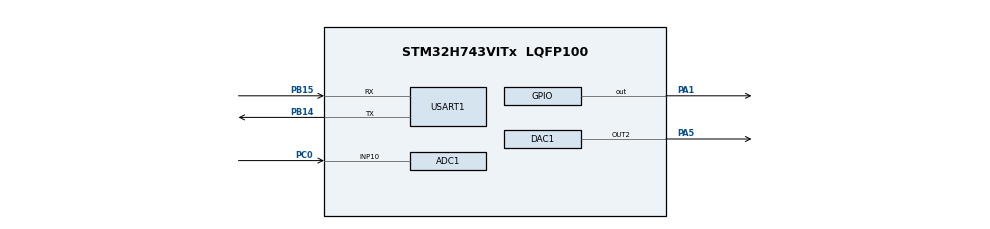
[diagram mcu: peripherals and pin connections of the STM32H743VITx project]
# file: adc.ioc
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ADC1.Channel-0\#ChannelRegularConversion=ADC_CHANNEL_10
ADC1.ConversionDataManagement=ADC_CONVERSIONDATA_DMA_CIRCULAR
ADC1.ExternalTrigConv=ADC_EXTERNALTRIG_T15_TRGO
ADC1.NbrOfConversion=1
ADC1.NbrOfConversionFlag=1
ADC1.OffsetNumber-0\#ChannelRegularConversion=ADC_OFFSET_NONE
ADC1.OffsetSignedSaturation-0\#ChannelRegularConversion=DISABLE
ADC1.Rank-0\#ChannelRegularConversion=1
ADC1.SamplingTime-0\#ChannelRegularConversion=ADC_SAMPLETIME_1CYCLE_5
ADC1.master=1
CORTEX_M7.AccessPermission-Cortex_Memory_Protection_Unit_Region0_Settings=MPU_REGION_FULL_ACCESS
CORTEX_M7.AccessPermission-Cortex_Memory_Protection_Unit_Region1_Settings=MPU_REGION_FULL_ACCESS
CORTEX_M7.AccessPermission-Cortex_Memory_Protection_Unit_Region2_Settings=MPU_REGION_FULL_ACCESS
CORTEX_M7.AccessPermission-Cortex_Memory_Protection_Unit_Region3_Settings=MPU_REGION_FULL_ACCESS
CORTEX_M7.AccessPermission-Cortex_Memory_Protection_Unit_Region4_Settings=MPU_REGION_FULL_ACCESS
CORTEX_M7.BaseAddress-Cortex_Memory_Protection_Unit_Region0_Settings=0x24000000
CORTEX_M7.BaseAddress-Cortex_Memory_Protection_Unit_Region1_Settings=0x30000000
CORTEX_M7.BaseAddress-Cortex_Memory_Protection_Unit_Region2_Settings=0x30020000
CORTEX_M7.BaseAddress-Cortex_Memory_Protection_Unit_Region3_Settings=0x30040000
CORTEX_M7.BaseAddress-Cortex_Memory_Protection_Unit_Region4_Settings=0x38000000
CORTEX_M7.CPU_DCache=Enabled
CORTEX_M7.CPU_ICache=Enabled
CORTEX_M7.Enable-Cortex_Memory_Protection_Unit_Region0_Settings=MPU_REGION_ENABLE
CORTEX_M7.Enable-Cortex_Memory_Protection_Unit_Region1_Settings=MPU_REGION_ENABLE
CORTEX_M7.Enable-Cortex_Memory_Protection_Unit_Region2_Settings=MPU_REGION_ENABLE
CORTEX_M7.Enable-Cortex_Memory_Protection_Unit_Region3_Settings=MPU_REGION_ENABLE
CORTEX_M7.Enable-Cortex_Memory_Protection_Unit_Region4_Settings=MPU_REGION_ENABLE
CORTEX_M7.Enable-Cortex_Memory_Protection_Unit_Region5_Settings=__NULL
CORTEX_M7.IsBufferable-Cortex_Memory_Protection_Unit_Region0_Settings=MPU_ACCESS_BUFFERABLE
CORTEX_M7.IsCacheable-Cortex_Memory_Protection_Unit_Region0_Settings=MPU_ACCESS_CACHEABLE
CORTEX_M7.MPU_Control=MPU_PRIVILEGED_DEFAULT
CORTEX_M7.Size-Cortex_Memory_Protection_Unit_Region0_Settings=MPU_REGION_SIZE_512KB
CORTEX_M7.Size-Cortex_Memory_Protection_Unit_Region1_Settings=MPU_REGION_SIZE_128KB
CORTEX_M7.Size-Cortex_Memory_Protection_Unit_Region2_Settings=MPU_REGION_SIZE_128KB
CORTEX_M7.Size-Cortex_Memory_Protection_Unit_Region3_Settings=MPU_REGION_SIZE_32KB
CORTEX_M7.Size-Cortex_Memory_Protection_Unit_Region4_Settings=MPU_REGION_SIZE_64KB
CORTEX_M7.TypeExtField-Cortex_Memory_Protection_Unit_Region0_Settings=MPU_TEX_LEVEL1
CORTEX_M7.TypeExtField-Cortex_Memory_Protection_Unit_Region1_Settings=MPU_TEX_LEVEL1
CORTEX_M7.TypeExtField-Cortex_Memory_Protection_Unit_Region2_Settings=MPU_TEX_LEVEL1
CORTEX_M7.TypeExtField-Cortex_Memory_Protection_Unit_Region3_Settings=MPU_TEX_LEVEL1
CORTEX_M7.TypeExtField-Cortex_Memory_Protection_Unit_Region4_Settings=MPU_TEX_LEVEL1
DAC1.DAC2_OutputBuffer-DAC_OUT2=DAC_OUTPUTBUFFER_DISABLE
DAC1.DAC_Channel-DAC_OUT2=DAC_CHANNEL_2
DAC1.DAC_Trigger-DAC_OUT2=DAC_TRIGGER_SOFTWARE
Dma.ADC1.0.Direction=DMA_PERIPH_TO_MEMORY
Dma.ADC1.0.EventEnable=DISABLE
Dma.ADC1.0.FIFOMode=DMA_FIFOMODE_DISABLE
Dma.ADC1.0.Instance=DMA1_Stream0
Dma.ADC1.0.MemDataAlignment=DMA_MDATAALIGN_HALFWORD
Dma.ADC1.0.MemInc=DMA_MINC_ENABLE
Dma.ADC1.0.Mode=DMA_NORMAL
Dma.ADC1.0.PeriphDataAlignment=DMA_PDATAALIGN_HALFWORD
Dma.ADC1.0.PeriphInc=DMA_PINC_DISABLE
Dma.ADC1.0.Polarity=HAL_DMAMUX_REQ_GEN_RISING
Dma.ADC1.0.Priority=DMA_PRIORITY_LOW
Dma.ADC1.0.RequestNumber=1
Dma.ADC1.0.SignalID=NONE
Dma.ADC1.0.SyncEnable=DISABLE
Dma.ADC1.0.SyncPolarity=HAL_DMAMUX_SYNC_NO_EVENT
Dma.ADC1.0.SyncRequestNumber=1
Dma.ADC1.0.SyncSignalID=NONE
Dma.DAC1_CH2.1.Direction=DMA_MEMORY_TO_PERIPH
Dma.DAC1_CH2.1.EventEnable=DISABLE
Dma.DAC1_CH2.1.FIFOMode=DMA_FIFOMODE_DISABLE
Dma.DAC1_CH2.1.Instance=DMA1_Stream1
Dma.DAC1_CH2.1.MemDataAlignment=DMA_MDATAALIGN_HALFWORD
Dma.DAC1_CH2.1.MemInc=DMA_MINC_ENABLE
Dma.DAC1_CH2.1.Mode=DMA_CIRCULAR
Dma.DAC1_CH2.1.PeriphDataAlignment=DMA_PDATAALIGN_HALFWORD
Dma.DAC1_CH2.1.PeriphInc=DMA_PINC_DISABLE
Dma.DAC1_CH2.1.Polarity=HAL_DMAMUX_REQ_GEN_RISING
Dma.DAC1_CH2.1.Priority=DMA_PRIORITY_LOW
Dma.DAC1_CH2.1.RequestNumber=1
Dma.DAC1_CH2.1.SignalID=NONE
Dma.DAC1_CH2.1.SyncEnable=DISABLE
Dma.DAC1_CH2.1.SyncPolarity=HAL_DMAMUX_SYNC_NO_EVENT
Dma.DAC1_CH2.1.SyncRequestNumber=1
Dma.DAC1_CH2.1.SyncSignalID=NONE
Dma.Request0=ADC1
Dma.Request1=DAC1_CH2
Mcu.Family=STM32H7
Mcu.Name=STM32H743VITx
Mcu.Package=LQFP100
NVIC.DMA1_Stream0_IRQn=true\:0\:0\:false\:false\:true\:false\:true\:true
NVIC.DMA1_Stream1_IRQn=true\:0\:0\:false\:false\:true\:false\:true\:true
NVIC.PriorityGroup=NVIC_PRIORITYGROUP_4
NVIC.USART1_IRQn=true\:0\:0\:false\:false\:true\:true\:true\:true
PA1.GPIO_PuPd=GPIO_PULLDOWN
PA1.Signal=GPIO_Output
PA13\ (JTMS/SWDIO).Mode=Serial_Wire
PA13\ (JTMS/SWDIO).Signal=DEBUG_JTMS-SWDIO
PA14\ (JTCK/SWCLK).Mode=Serial_Wire
PA14\ (JTCK/SWCLK).Signal=DEBUG_JTCK-SWCLK
PA5.Signal=COMP_DAC12_group
PB14.Mode=Asynchronous
PB14.Signal=USART1_TX
PB15.Mode=Asynchronous
PB15.Signal=USART1_RX
PC0.Signal=ADCx_INP10
PH0-OSC_IN\ (PH0).Mode=HSE-External-Oscillator
PH0-OSC_IN\ (PH0).Signal=RCC_OSC_IN
PH1-OSC_OUT\ (PH1).Mode=HSE-External-Oscillator
PH1-OSC_OUT\ (PH1).Signal=RCC_OSC_OUT
ProjectManager.HeapSize=0x200
ProjectManager.StackSize=0x7400
ProjectManager.TargetToolchain=MDK-ARM V5.32
RCC.ADCFreq_Value=72000000
RCC.APB1Freq_Value=120000000
RCC.APB2Freq_Value=120000000
RCC.APB3Freq_Value=120000000
RCC.APB4Freq_Value=120000000
RCC.CSICalibrationValue=32
RCC.CortexFreq_Value=480000000
RCC.D1PPRE=RCC_APB3_DIV2
RCC.D2PPRE1=RCC_APB1_DIV2
RCC.D2PPRE2=RCC_APB2_DIV2
RCC.D3PPRE=RCC_APB4_DIV2
RCC.DIVM1=5
RCC.DIVM2=25
RCC.DIVN1=192
RCC.DIVN2=360
RCC.DIVP2=5
RCC.FLatency=FLASH_LATENCY_4
RCC.HCLKFreq_Value=240000000
RCC.HPRE=RCC_HCLK_DIV2
RCC.HSE_Timout=5000
RCC.PLLSourceVirtual=RCC_PLLSOURCE_HSE
RCC.ProductRev=revV
RCC.SYSCLKFreq_VALUE=480000000
RCC.SYSCLKSource=RCC_SYSCLKSOURCE_PLLCLK
RCC.USBFreq_Value=480000000
SH.ADCx_INP10.0=ADC1_INP10,IN10-Single-Ended
SH.COMP_DAC12_group.0=DAC1_OUT2,DAC_OUT2
STMicroelectronics.X-CUBE-ALGOBUILD.1.3.0.LibraryCcDSPOoLibraryJjDSPOoLibrary=true
TIM15.AutoReloadPreload=TIM_AUTORELOAD_PRELOAD_ENABLE
TIM15.Period=2399
TIM15.Prescaler=0
TIM15.TIM_MasterOutputTrigger=TIM_TRGO_UPDATE
TIM7.Prescaler=239
USART1.VirtualMode-Asynchronous=VM_ASYNC
VP_STMicroelectronics.X-CUBE-ALGOBUILD_VS_DSPOoLibraryJjLibrary_1.3.0_1.3.0.Mode=DSPOoLibraryJjLibrary
VP_TIM15_VS_ClockSourceINT.Mode=Internal
VP_TIM7_VS_ClockSourceINT.Mode=Enable_Timer
board=custom

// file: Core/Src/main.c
/* USER CODE BEGIN Header */
/**
  ******************************************************************************
  * @file           : main.c
  * @brief          : Main program body
  ******************************************************************************
  * @attention
  *
  * Copyright (c) 2023 STMicroelectronics.
  * All rights reserved.
  *
  * This software is licensed under terms that can be found in the LICENSE file
  * in the root directory of this software component.
  * If no LICENSE file comes with this software, it is provided AS-IS.
  *
  ******************************************************************************
  */
/* USER CODE END Header */
#include "main.h"
#include "adc.h"
#include "dac.h"
#include "dma.h"
#include "tim.h"
#include "usart.h"
#include "gpio.h"

/* USER CODE BEGIN PTD */

//ALIGN_32BYTES (uint16_t adc1_data[FFT_LENGTH]) 	__attribute__((section(".ARM.__at_0x30000000")));
//__IO uint8_t AdcConvEnd = 0;//表示adc采集完成
//void adc_init(void)
//{
//	printf("start_adc\n");
//	MX_ADC1_Init();	//初始化调用放这里, 确保在MX_DMA_Init()初始化后面
//	HAL_Delay(100);	//有地方说这里可以等等电压稳定后再校准

//	if (HAL_ADCEx_Calibration_Start(&hadc1, ADC_CALIB_OFFSET, ADC_SINGLE_ENDED) != HAL_OK)
//	{
//			printf("hadc1 error with HAL_ADCEx_Calibration_Start\r\n");
//			Error_Handler();
//	}

//	if (HAL_ADC_Start_DMA(&hadc1, (uint32_t *)adc1_data, FFT_LENGTH) != HAL_OK)
//	{
//			printf("hadc1 error with HAL_ADC_Start_DMA\r\n");
//			Error_Handler();
//	}

//	HAL_TIM_Base_Start(&htim15);
//	while (!AdcConvEnd);
//	AdcConvEnd = 0;
//	HAL_ADC_DeInit(&hadc1);
//	HAL_TIM_Base_Stop(&htim15);
//}
/* USER CODE END PTD */

/* USER CODE BEGIN PV */
uint16_t adc_buff[200];//存放ADC采集的数据
/*
AdcConvEnd用来检测ADC是否采集完毕
0：没有采集完毕
1：采集完毕，在stm32f1xx_it里的DMA完成中断进行修改
 */
__IO uint8_t AdcConvEnd = 0;

/* USER CODE END PV */

void SystemClock_Config(void);
static void MPU_Initialize(void);
static void MPU_Config(void);

int main(void)
{

  /* Enable I-Cache---------------------------------------------------------*/
  SCB_EnableICache();

  /* Enable D-Cache---------------------------------------------------------*/
  SCB_EnableDCache();

  /* MCU Configuration--------------------------------------------------------*/

  /* Reset of all peripherals, Initializes the Flash interface and the Systick. */
  HAL_Init();

  /* MPU Configuration--------------------------------------------------------*/
  MPU_Config();

  /* Configure the system clock */
  SystemClock_Config();

  /* Initialize all configured peripherals */
  MX_GPIO_Init();
  MX_DMA_Init();
  MX_USART1_UART_Init();
  MX_ADC1_Init();
  MX_TIM7_Init();
  MX_DAC1_Init();
  MX_TIM15_Init();
  /* USER CODE BEGIN 2 */
  HAL_TIM_Base_Start(&htim15);                           //开启定时器3
//HAL_ADCEx_Calibration_Start(&hadc1);                  //AD校准
HAL_ADC_Start_DMA(&hadc1, (uint32_t *)adc_buff, 200); //让ADC1去采集200个数，存放到adc_buff数组里
while (!AdcConvEnd)                                   //等待转换完毕
    ;
for (uint16_t i = 0; i < 200; i++)
{
    printf("%.3f\n", adc_buff[i] * 3.3 / 4095); //数据打印，查看结果
}

//  HAL_DAC_SetValue(&hdac1,DAC_CHANNEL_2,DAC_ALIGN_12B_R,4095);
//  HAL_DAC_Start(&hdac1,DAC_CHANNEL_2);
//
//  adc_init();
//  for (u16 temp = 0; temp< FFT_LENGTH;temp++)
//	{
//		printf("%d\r\n", adc1_data[temp]);
//	}
  /* USER CODE END 2 */

  /* Infinite loop */
  while (1)
  {

  }
}

void SystemClock_Config(void)
{
  RCC_OscInitTypeDef RCC_OscInitStruct = {0};
  RCC_ClkInitTypeDef RCC_ClkInitStruct = {0};

  /** Supply configuration update enable
  */
  HAL_PWREx_ConfigSupply(PWR_LDO_SUPPLY);

  /** Configure the main internal regulator output voltage
  */
  __HAL_PWR_VOLTAGESCALING_CONFIG(PWR_REGULATOR_VOLTAGE_SCALE1);

  while(!__HAL_PWR_GET_FLAG(PWR_FLAG_VOSRDY)) {}

  __HAL_RCC_SYSCFG_CLK_ENABLE();
  __HAL_PWR_VOLTAGESCALING_CONFIG(PWR_REGULATOR_VOLTAGE_SCALE0);

  while(!__HAL_PWR_GET_FLAG(PWR_FLAG_VOSRDY)) {}

  /** Initializes the RCC Oscillators according to the specified parameters
  * in the RCC_OscInitTypeDef structure.
  */
  RCC_OscInitStruct.OscillatorType = RCC_OSCILLATORTYPE_HSE;
  RCC_OscInitStruct.HSEState = RCC_HSE_ON;
  RCC_OscInitStruct.PLL.PLLState = RCC_PLL_ON;
  RCC_OscInitStruct.PLL.PLLSource = RCC_PLLSOURCE_HSE;
  RCC_OscInitStruct.PLL.PLLM = 5;
  RCC_OscInitStruct.PLL.PLLN = 192;
  RCC_OscInitStruct.PLL.PLLP = 2;
  RCC_OscInitStruct.PLL.PLLQ = 2;
  RCC_OscInitStruct.PLL.PLLR = 2;
  RCC_OscInitStruct.PLL.PLLRGE = RCC_PLL1VCIRANGE_2;
  RCC_OscInitStruct.PLL.PLLVCOSEL = RCC_PLL1VCOWIDE;
  RCC_OscInitStruct.PLL.PLLFRACN = 0;
  if (HAL_RCC_OscConfig(&RCC_OscInitStruct) != HAL_OK)
  {
    Error_Handler();
  }

  /** Initializes the CPU, AHB and APB buses clocks
  */
  RCC_ClkInitStruct.ClockType = RCC_CLOCKTYPE_HCLK|RCC_CLOCKTYPE_SYSCLK
                              |RCC_CLOCKTYPE_PCLK1|RCC_CLOCKTYPE_PCLK2
                              |RCC_CLOCKTYPE_D3PCLK1|RCC_CLOCKTYPE_D1PCLK1;
  RCC_ClkInitStruct.SYSCLKSource = RCC_SYSCLKSOURCE_PLLCLK;
  RCC_ClkInitStruct.SYSCLKDivider = RCC_SYSCLK_DIV1;
  RCC_ClkInitStruct.AHBCLKDivider = RCC_HCLK_DIV2;
  RCC_ClkInitStruct.APB3CLKDivider = RCC_APB3_DIV2;
  RCC_ClkInitStruct.APB1CLKDivider = RCC_APB1_DIV2;
  RCC_ClkInitStruct.APB2CLKDivider = RCC_APB2_DIV2;
  RCC_ClkInitStruct.APB4CLKDivider = RCC_APB4_DIV2;

  if (HAL_RCC_ClockConfig(&RCC_ClkInitStruct, FLASH_LATENCY_4) != HAL_OK)
  {
    Error_Handler();
  }
}

/* USER CODE BEGIN 4 */
void HAL_ADC_ConvCpltCallback(ADC_HandleTypeDef* hadc)
{
   if(hadc->Instance == ADC1)
	{
      //SCB_InvalidateDCache_by_Addr((uint32_t *) &adc1_data[0], ADC1_BUFFER_SIZE);
   }
	 AdcConvEnd = 1;
}
/* USER CODE END 4 */

/* MPU Configuration */

void MPU_Config(void)
{
  MPU_Region_InitTypeDef MPU_InitStruct = {0};

  /* Disables the MPU */
  HAL_MPU_Disable();

  /** Initializes and configures the Region and the memory to be protected
  */
  MPU_InitStruct.Enable = MPU_REGION_ENABLE;
  MPU_InitStruct.Number = MPU_REGION_NUMBER0;
  MPU_InitStruct.BaseAddress = 0x24000000;
  MPU_InitStruct.Size = MPU_REGION_SIZE_512KB;
  MPU_InitStruct.SubRegionDisable = 0x0;
  MPU_InitStruct.TypeExtField = MPU_TEX_LEVEL1;
  MPU_InitStruct.AccessPermission = MPU_REGION_FULL_ACCESS;
  MPU_InitStruct.DisableExec = MPU_INSTRUCTION_ACCESS_ENABLE;
  MPU_InitStruct.IsShareable = MPU_ACCESS_NOT_SHAREABLE;
  MPU_InitStruct.IsCacheable = MPU_ACCESS_CACHEABLE;
  MPU_InitStruct.IsBufferable = MPU_ACCESS_BUFFERABLE;

  HAL_MPU_ConfigRegion(&MPU_InitStruct);

  /** Initializes and configures the Region and the memory to be protected
  */
  MPU_InitStruct.Number = MPU_REGION_NUMBER1;
  MPU_InitStruct.BaseAddress = 0x30000000;
  MPU_InitStruct.Size = MPU_REGION_SIZE_128KB;
  MPU_InitStruct.IsCacheable = MPU_ACCESS_NOT_CACHEABLE;
  MPU_InitStruct.IsBufferable = MPU_ACCESS_NOT_BUFFERABLE;

  HAL_MPU_ConfigRegion(&MPU_InitStruct);

  /** Initializes and configures the Region and the memory to be protected
  */
  MPU_InitStruct.Number = MPU_REGION_NUMBER2;
  MPU_InitStruct.BaseAddress = 0x30020000;

  HAL_MPU_ConfigRegion(&MPU_InitStruct);

  /** Initializes and configures the Region and the memory to be protected
  */
  MPU_InitStruct.Number = MPU_REGION_NUMBER3;
  MPU_InitStruct.BaseAddress = 0x30040000;
  MPU_InitStruct.Size = MPU_REGION_SIZE_32KB;

  HAL_MPU_ConfigRegion(&MPU_InitStruct);

  /** Initializes and configures the Region and the memory to be protected
  */
  MPU_InitStruct.Number = MPU_REGION_NUMBER4;
  MPU_InitStruct.BaseAddress = 0x38000000;
  MPU_InitStruct.Size = MPU_REGION_SIZE_64KB;

  HAL_MPU_ConfigRegion(&MPU_InitStruct);
  /* Enables the MPU */
  HAL_MPU_Enable(MPU_PRIVILEGED_DEFAULT);

}

void Error_Handler(void)
{
  __disable_irq();
  while (1)
  {
  }
}
